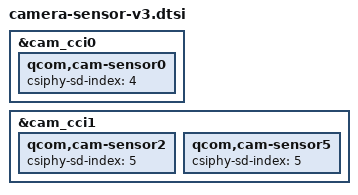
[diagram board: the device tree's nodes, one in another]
#include "camera-sensor.dtsi"

&cam_cci0 {
	/* back main sensor */
	qcom,cam-sensor0 {
		csiphy-sd-index = <4>;
	};
};

&cam_cci1 {
	/* front sensor */
	qcom,cam-sensor2 {
		csiphy-sd-index = <5>;
	};

	/* front swing sensor */
	qcom,cam-sensor5 {
		csiphy-sd-index = <5>;
	};
};
